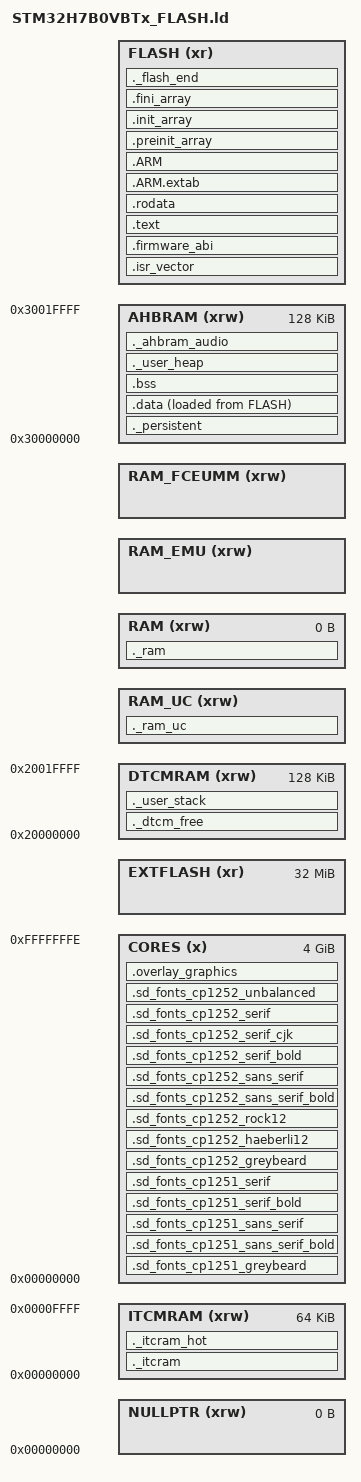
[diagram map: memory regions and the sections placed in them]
/*
******************************************************************************
**

**  File        : LinkerScript.ld
**
**  Author		: Auto-generated by System Workbench for STM32
**
**  Abstract    : Linker script for STM32H7B0VBTx series
**                128Kbytes FLASH and 1216Kbytes RAM
**
**                Set heap size, stack size and stack location according
**                to application requirements.
**
**                Set memory bank area and size if external memory is used.
**
**  Target      : STMicroelectronics STM32
**
**  Distribution: The file is distributed “as is,” without any warranty
**                of any kind.
**
*****************************************************************************
** @attention
**
** <h2><center>&copy; COPYRIGHT(c) 2019 STMicroelectronics</center></h2>
**
** Redistribution and use in source and binary forms, with or without modification,
** are permitted provided that the following conditions are met:
**   1. Redistributions of source code must retain the above copyright notice,
**      this list of conditions and the following disclaimer.
**   2. Redistributions in binary form must reproduce the above copyright notice,
**      this list of conditions and the following disclaimer in the documentation
**      and/or other materials provided with the distribution.
**   3. Neither the name of STMicroelectronics nor the names of its contributors
**      may be used to endorse or promote products derived from this software
**      without specific prior written permission.
**
** THIS SOFTWARE IS PROVIDED BY THE COPYRIGHT HOLDERS AND CONTRIBUTORS "AS IS"
** AND ANY EXPRESS OR IMPLIED WARRANTIES, INCLUDING, BUT NOT LIMITED TO, THE
** IMPLIED WARRANTIES OF MERCHANTABILITY AND FITNESS FOR A PARTICULAR PURPOSE ARE
** DISCLAIMED. IN NO EVENT SHALL THE COPYRIGHT HOLDER OR CONTRIBUTORS BE LIABLE
** FOR ANY DIRECT, INDIRECT, INCIDENTAL, SPECIAL, EXEMPLARY, OR CONSEQUENTIAL
** DAMAGES (INCLUDING, BUT NOT LIMITED TO, PROCUREMENT OF SUBSTITUTE GOODS OR
** SERVICES; LOSS OF USE, DATA, OR PROFITS; OR BUSINESS INTERRUPTION) HOWEVER
** CAUSED AND ON ANY THEORY OF LIABILITY, WHETHER IN CONTRACT, STRICT LIABILITY,
** OR TORT (INCLUDING NEGLIGENCE OR OTHERWISE) ARISING IN ANY WAY OUT OF THE USE
** OF THIS SOFTWARE, EVEN IF ADVISED OF THE POSSIBILITY OF SUCH DAMAGE.
**
*****************************************************************************
*/

/* Entry Point */
ENTRY(Reset_Handler)

/* Highest address of the user mode stack */
_estack = _stack_top;    /* end of RAM */

/* Stack is fixed at the top of DTCM (fast). Firmware .persistent, .data,
 * .bss and the stdlib heap live in AHB SRAM below the .audio DMA reserve
 * (AHB SRAM clock enabled via DATA_IN_D2_SRAM in SystemInit). dtc_malloc
 * bumps the free space between DTCM ORIGIN and the stack. */
/* Stack + redzone occupy exactly 20 KiB at the top of DTCM. Redzone is the
 * low 32 bytes of that window (overflow edge; stack grows downward). */
_Stack_Redzone_Size = 32;
_Min_Stack_Size = 20 * 1024 - _Stack_Redzone_Size;


/* Useful for scripts */
//__NULLPTR_LENGTH__  = 0x100;
__NULLPTR_LENGTH__  = 0x0;
__ITCMRAM_LENGTH__  = 64K;
__DTCMRAM_LENGTH__  = 128K;
/* __RAM_UC_LENGTH__ / __RAM_EMU_LENGTH__ / __RAM_START__ / __RAM_EMU_START__ /
 * __RAM_EMU_END__ come from ld/gnw_ram_emu.ld, shared with every standalone
 * core's linker script so the VMA a core is built for can never drift from
 * where the firmware actually loads it (see run_dynamic_core()). The values
 * are identical to the ones this file used to hand-roll; taking them from the
 * shared file is what stops flash and SD firmware loading the same
 * /cores/*.bin at different addresses. */
INCLUDE ld/gnw_ram_emu.ld
/* __ITCM_CORE_START__/__ITCM_CORE_LENGTH__ come from ld/gnw_itcm_core.ld
 * (shared with cores that place hot code in ITCM). */
INCLUDE ld/gnw_itcm_core.ld
/* __RAM_UC_CORE_* (LUT8 LCD-bonus window) from ld/gnw_ram_uc_core.ld. */
INCLUDE ld/gnw_ram_uc_core.ld
/* Legacy zero-length region: the MEMORY block's RAM entry and the ._ram
 * NOLOAD section that targets it still reference these. */
__RAM_CORE_LENGTH__ = 0K;
__RAM_FCEUMM_MAPPER_LENGTH__ = 48K; /* Current FCEUMM mapper code */
__AHBRAM_LENGTH__   = 128K;
__AHBRAM_PERSISTENT_RESERVE__ = 8K; /* MPU non-cacheable: boot_magic/logbuf + remote-input */
__AHBRAM_REMOTE_INPUT_RESERVE__ = 12; /* last bytes of persistent pad; scripts/remote_input.py */
__AHBRAM_AUDIO_RESERVE__ = 8K; /* MPU non-cacheable slot for .audio DMA buffer at end of AHB SRAM */
__FLASH_LENGTH__    = DEFINED(__FLASH_LENGTH__) ? __FLASH_LENGTH__ : 128k;

__EXTFLASH_OFFSET__ = DEFINED(__EXTFLASH_OFFSET__) ? __EXTFLASH_OFFSET__ : 0;
__EXTFLASH_BASE__ = 0x90000000;  /* Beginning of addressable extflash addresses */
__EXTFLASH_START__ = __EXTFLASH_BASE__ + __EXTFLASH_OFFSET__;  /* Beginning of where we're going to store emulator and rom data */

__RAM_UC_START__    = __RAM_START__;
__RAM_CORE_START__  = __RAM_EMU_START__;
__RAM_FCEUMM_START__ = __RAM_EMU_START__ + __RAM_FCEUMM_MAPPER_LENGTH__;

__RAM_END__         = __RAM_START__ + 1024K;

/****
 * External Flash Layout
 *
 * 0x90000000 +----------------------------------+  __EXTFLASH_BASE__
 *            |                                  |
 *            |        Untouched data if         |
 *            | __EXTFLASH_OFFSET__ is specified |
 *            |                                  |
 *            +----------------------------------+  __EXTFLASH_START__
 *            |                                  |
 *            |     FrogFS image (frogfs.bin)    |
 *            |                                  |
 *            +----------------------------------+
 *            |                                  |
 *            |         Possibly Unused          |
 *            |                                  |
 *            +----------------------------------+  __EXTFLASH_END__ __FILESYSTEM_START__
 *            |                                  |
 *            |        LittleFS partition        |
 *            |                                  |
 *            +----------------------------------+  __FILESYSTEM_END__ __EXTFLASH_END__
 */
__EXTFLASH_LENGTH__ = __EXTFLASH_TOTAL_LENGTH__;
__EXTFLASH_END__ = __EXTFLASH_START__ + __EXTFLASH_LENGTH__;

__FILESYSTEM_START__ = __EXTFLASH_START__ + __FILESYSTEM_OFFSET__;
__FILESYSTEM_END__ = __FILESYSTEM_START__ + __FILESYSTEM_LENGTH__;

/* scripts/size.sh: no ELF-linked payload in external flash (FrogFS is a separate binary). */
__extflash_start__ = __EXTFLASH_START__;
__extflash_end__ = __EXTFLASH_START__;


__INTFLASH__ = DEFINED(__INTFLASH__) ? __INTFLASH__ : 0x08000000;

/* Specify the memory areas */
MEMORY
{
  /* RAM */
  NULLPTR  (xrw) : ORIGIN = 0x00000000, LENGTH =   __NULLPTR_LENGTH__
  ITCMRAM  (xrw) : ORIGIN = 0x00000000 + __NULLPTR_LENGTH__, LENGTH = __ITCMRAM_LENGTH__ - __NULLPTR_LENGTH__
  DTCMRAM  (xrw) : ORIGIN = 0x20000000, LENGTH =  __DTCMRAM_LENGTH__
  RAM_UC   (xrw) : ORIGIN = __RAM_UC_START__, LENGTH = __RAM_UC_LENGTH__
  RAM      (xrw) : ORIGIN = __RAM_CORE_START__, LENGTH = __RAM_CORE_LENGTH__
  RAM_EMU  (xrw) : ORIGIN = __RAM_EMU_START__, LENGTH = __RAM_EMU_LENGTH__
  RAM_FCEUMM (xrw) : ORIGIN = __RAM_FCEUMM_START__, LENGTH = __RAM_EMU_LENGTH__ - __RAM_FCEUMM_MAPPER_LENGTH__
  AHBRAM   (xrw) : ORIGIN = 0x30000000, LENGTH =  __AHBRAM_LENGTH__

  /* FLASH */
  FLASH      (xr ) : ORIGIN = __INTFLASH__,          LENGTH =  __FLASH_LENGTH__
  CORES      (x  ) : ORIGIN = 0x0,                 LENGTH = 0xFFFFFFFF
  EXTFLASH   (xr ) : ORIGIN = __EXTFLASH_START__,  LENGTH = 32M
}


/* Define output sections */
SECTIONS
{
  ._itcram :
  {
    __itcram_start__ = .;
    . = ALIGN(4);
    *(.itcram_data)
    . = ALIGN(4);
    *(.itcram_text)
    . = ALIGN(4);
  } > ITCMRAM

  ._itcram_hot :
  {
    __itcram_hot_start__ = .;
    __itcram_hot_end__ = .;
    __itcram_end__ = .;
  } >ITCMRAM

  /* Same guard as STM32H7B0VBTx_SDCARD.ld: a core's fixed ITCM segment starts
   * at __ITCM_CORE_START__ (0), which is only safe while the firmware itself
   * places nothing in ITCM. Fail the build loudly rather than silently
   * corrupting a loaded core's ITCM segment. */
  ASSERT(__ITCM_CORE_START__ == __itcram_hot_start__,
         "Error: ld/gnw_itcm_core.ld's __ITCM_CORE_START__ no longer matches __itcram_hot_start__ — a core's fixed ITCM segment would overlap firmware-resident ITCM data")

  /* LCD framebuffer pool (300 KiB). RGB565 fills it with two 150 KiB
   * framebuffers. LUT8 shrinks that footprint to 150 KiB; the upper
   * 150 KiB is the cacheable GNW_CORE_REGION_RAM_UC window
   * (__RAM_UC_CORE_START__, see ld/gnw_ram_uc_core.ld) plus leftover
   * heap from lcd_get_bonus_pool(). */
  ._ram_uc (NOLOAD) :
  {
    __ram_uc_start__ = .;
    . = ALIGN(16);
    __lcd_pool_start__ = .;
    . = . + __RAM_UC_LENGTH__;
    __lcd_pool_end__ = .;
    __ram_uc_end__ = .;
  } > RAM_UC

  ASSERT(__lcd_pool_start__ + __RAM_UC_FB_BYTES__ == __RAM_UC_CORE_START__,
         "Error: LUT8 core window must start immediately after the LUT8 double framebuffer")
  ASSERT(__RAM_UC_CORE_START__ + __RAM_UC_CORE_LENGTH__ == __RAM_EMU_START__,
         "Error: LUT8 core window (ld/gnw_ram_uc_core.ld) must sit exactly between the LUT8 framebuffers and RAM_EMU")

  .sd_fonts_cp1251_greybeard : {
    . = ALIGN(4);
    KEEP(*(.sd_fonts_cp1251_greybeard))
  } > CORES

  .sd_fonts_cp1251_sans_serif_bold : {
    . = ALIGN(4);
    KEEP(*(.sd_fonts_cp1251_sans_serif_bold))
  } > CORES

  .sd_fonts_cp1251_sans_serif : {
    . = ALIGN(4);
    KEEP(*(.sd_fonts_cp1251_sans_serif))
  } > CORES

  .sd_fonts_cp1251_serif_bold : {
    . = ALIGN(4);
    KEEP(*(.sd_fonts_cp1251_serif_bold))
  } > CORES

  .sd_fonts_cp1251_serif : {
    . = ALIGN(4);
    KEEP(*(.sd_fonts_cp1251_serif))
  } > CORES

  .sd_fonts_cp1252_greybeard : {
    . = ALIGN(4);
    KEEP(*(.sd_fonts_cp1252_greybeard))
  } > CORES

  .sd_fonts_cp1252_haeberli12 : {
    . = ALIGN(4);
    KEEP(*(.sd_fonts_cp1252_haeberli12))
  } > CORES

  .sd_fonts_cp1252_rock12 : {
    . = ALIGN(4);
    KEEP(*(.sd_fonts_cp1252_rock12))
  } > CORES

  .sd_fonts_cp1252_sans_serif_bold : {
    . = ALIGN(4);
    KEEP(*(.sd_fonts_cp1252_sans_serif_bold))
  } > CORES

  .sd_fonts_cp1252_sans_serif : {
    . = ALIGN(4);
    KEEP(*(.sd_fonts_cp1252_sans_serif))
  } > CORES

  .sd_fonts_cp1252_serif_bold : {
    . = ALIGN(4);
    KEEP(*(.sd_fonts_cp1252_serif_bold))
  } > CORES

  .sd_fonts_cp1252_serif_cjk : {
    . = ALIGN(4);
    KEEP(*(.sd_fonts_cp1252_serif_cjk))
  } > CORES

  .sd_fonts_cp1252_serif : {
    . = ALIGN(4);
    KEEP(*(.sd_fonts_cp1252_serif))
  } > CORES

  .sd_fonts_cp1252_unbalanced : {
    . = ALIGN(4);
    KEEP(*(.sd_fonts_cp1252_unbalanced))
  } > CORES

  .overlay_graphics : {
    . = ALIGN(4);
    KEEP(*(.sdcard_logo))
  } > CORES

  /* Every classic emulator's .overlay_<system>/.overlay_<system>_bss RAM
   * overlay (tgb, msx, wsv, gw, a2600, a7800, amstrad, videopac, celeste,
   * tama, pkmini, zelda3/rodata_zelda3, smw) has been removed while
   * migrating those systems to standalone cores/<system>/ builds loaded
   * from /cores/*.bin at runtime. They all shared the same
   * __RAM_EMU_START__ VMA (only one core is ever resident at a time), so
   * removing them is safe; re-adding one is a copy of an old git revision
   * of this file, not a from-scratch design. The LUT8 core window
   * (__RAM_UC_CORE_START__, ld/gnw_ram_uc_core.ld) and the graphics/font
   * sections are untouched. Mirrors the same removal already done in
   * STM32H7B0VBTx_SDCARD.ld. */

  ._ram (NOLOAD) :
  {
    . = ALIGN(4);
    *(.emulator_data)
    __ram_end__ = .;
  } > RAM

  /* The startup code goes first into FLASH */
  .isr_vector :
  {
    __flash_start__ = .;
    . = ALIGN(4);
    KEEP(*(.isr_vector)) /* Startup code */
    . = ALIGN(4);
  } >FLASH

  /* Firmware ABI table at fixed offset 0x400 from intflash start.
     See SDCARD linker + Core/Inc/retro-go/gw_firmware_abi.h. */
  .firmware_abi ORIGIN(FLASH) + 0x400 :
  {
    KEEP(*(.firmware_abi))
  } >FLASH

  /* The program code and other data goes into FLASH */
  .text :
  {
    . = ALIGN(4);
    *(.text)           /* .text sections (code) */
    *(.text*)          /* .text* sections (code) */
    *(.glue_7)         /* glue arm to thumb code */
    *(.glue_7t)        /* glue thumb to arm code */
    *(.eh_frame)

    KEEP (*(.init))
    KEEP (*(.fini))

    . = ALIGN(4);
    _etext = .;        /* define a global symbols at end of code */
  } >FLASH

  /* Constant data goes into FLASH */
  .rodata :
  {
    . = ALIGN(4);
    *(.rodata)         /* .rodata sections (constants, strings, etc.) */
    *(.rodata*)        /* .rodata* sections (constants, strings, etc.) */
    _intflash_logo_start = .;
    *(.intflash_logo)
    _intflash_logo_end = .;
    _intflash_global_start = .;
    *(.intflash_global)
    _intflash_global_end = .;
    . = ALIGN(4);
  } >FLASH

  .ARM.extab   : { *(.ARM.extab* .gnu.linkonce.armextab.*) } >FLASH
  .ARM : {
    __exidx_start = .;
    *(.ARM.exidx*)
    __exidx_end = .;
  } >FLASH

  .preinit_array     :
  {
    PROVIDE_HIDDEN (__preinit_array_start = .);
    KEEP (*(.preinit_array*))
    PROVIDE_HIDDEN (__preinit_array_end = .);
  } >FLASH
  .init_array :
  {
    PROVIDE_HIDDEN (__init_array_start = .);
    KEEP (*(SORT(.init_array.*)))
    KEEP (*(.init_array*))
    PROVIDE_HIDDEN (__init_array_end = .);
  } >FLASH
  .fini_array :
  {
    PROVIDE_HIDDEN (__fini_array_start = .);
    KEEP (*(SORT(.fini_array.*)))
    KEEP (*(.fini_array*))
    PROVIDE_HIDDEN (__fini_array_end = .);
  } >FLASH

  /* AHB SRAM: .persistent + .data/.bss + newlib heap + .audio.
   * LMA for .data must follow FLASH sections above.
   * Requires DATA_IN_D2_SRAM so SystemInit enables AHB SRAM before crt0.
   * .persistent padded to 8K for an MPU non-cacheable region (OCD logbuf).
   * Last 12 bytes hold the remote-input shadow word (was DTCM 0x2001FFF4). */
  ._persistent (NOLOAD) :
  {
    __ahbram_start__ = .;
    . = ALIGN(4);
    *(.persistent_boot_magic)
    *(.persistent_log_idx)
    *(.persistent_logbuf)
    . = ALIGN(4);
    ASSERT(. <= ORIGIN(AHBRAM) + __AHBRAM_PERSISTENT_RESERVE__ - __AHBRAM_REMOTE_INPUT_RESERVE__,
           "AHB .persistent overflows pad before remote-input reserve");
    . = ORIGIN(AHBRAM) + __AHBRAM_PERSISTENT_RESERVE__ - __AHBRAM_REMOTE_INPUT_RESERVE__;
    __remote_input__ = .;
    . = ORIGIN(AHBRAM) + __AHBRAM_PERSISTENT_RESERVE__;
  } > AHBRAM

  _sidata = LOADADDR(.data);

  .data :
  {
    . = ALIGN(4);
    _sdata = .;
    *(.littlefs_cfg)
    *(.data)
    *(.data*)

    . = ALIGN(4);
    _edata = .;
  } > AHBRAM AT> FLASH

  ._flash_end :
  {
    . = ALIGN(4);
    __flash_end__ = .;
  } >FLASH

  .bss (NOLOAD) :
  {
    . = ALIGN(4);
    _sbss = .;
    __bss_start__ = _sbss;
    *(.bss)
    *(.bss*)
    *(COMMON)

    . = ALIGN(4);
    _ebss = .;
    __bss_end__ = _ebss;
  } > AHBRAM

  ._user_heap (NOLOAD) :
  {
    . = ALIGN(16);
    __ahbram_heap_start__ = .;
    _heap_start = .;

    _heap_end = ORIGIN(AHBRAM) + LENGTH(AHBRAM) - __AHBRAM_AUDIO_RESERVE__;
    ASSERT(_heap_start < _heap_end,
           "AHB overflow: .persistent/.data/.bss leave no room for malloc heap before .audio");
    . = _heap_end;
  } > AHBRAM

  ._ahbram_audio (NOLOAD) :
  {
    __ahbram_audio_start__ = .;
    *(.audio)
    . = ALIGN(4);
    __ahbram_end__ = .;
  } > AHBRAM

  /* DTCM: bump pool from ORIGIN up to the stack redzone. */
  ._dtcm_free (NOLOAD) :
  {
    . = ALIGN(16);
    __dtcram_start__ = .;
    __dtc_padding_start__ = .;
    . = ORIGIN(DTCMRAM) + __DTCMRAM_LENGTH__
        - _Min_Stack_Size
        - _Stack_Redzone_Size;
    __dtc_padding_end__ = .;
  } >DTCMRAM

  ._user_stack (NOLOAD) :
  {
    _stack_redzone = .;
    . = . + _Stack_Redzone_Size;
    _stack_bottom = .;
    . = . + _Min_Stack_Size;
    _stack_top = .;
    __dtcram_end__ = .;
  } >DTCMRAM

  /* Remove information from the standard libraries */
  /DISCARD/ :
  {
    libc.a ( * )
    libm.a ( * )
    libgcc.a ( * )
  }

  .ARM.attributes 0 : { *(.ARM.attributes) }
}
